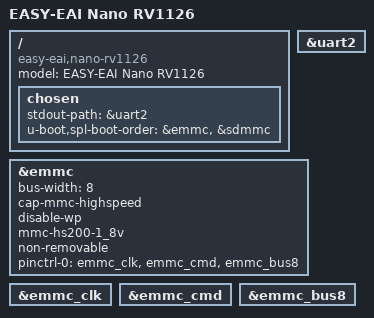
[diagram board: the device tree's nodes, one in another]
// SPDX-License-Identifier: (GPL-2.0+ OR MIT)
/*
 * Minimal U-Boot device tree for the EASY-EAI Nano RV1126.
 */

/dts-v1/;

#include "rv1126.dtsi"
#include "rv1126-u-boot.dtsi"

/ {
	model = "EASY-EAI Nano RV1126";
	compatible = "easy-eai,nano-rv1126", "rockchip,rv1126";

	chosen {
		stdout-path = &uart2;
		u-boot,spl-boot-order = &emmc, &sdmmc;
	};
};

&uart2 {
	status = "okay";
};

&emmc {
	u-boot,dm-spl;
	bus-width = <8>;
	cap-mmc-highspeed;
	disable-wp;
	mmc-hs200-1_8v;
	non-removable;
	pinctrl-names = "default";
	pinctrl-0 = <&emmc_clk &emmc_cmd &emmc_bus8>;
	status = "okay";
};

&emmc_clk {
	u-boot,dm-spl;
};

&emmc_cmd {
	u-boot,dm-spl;
};

&emmc_bus8 {
	u-boot,dm-spl;
};
